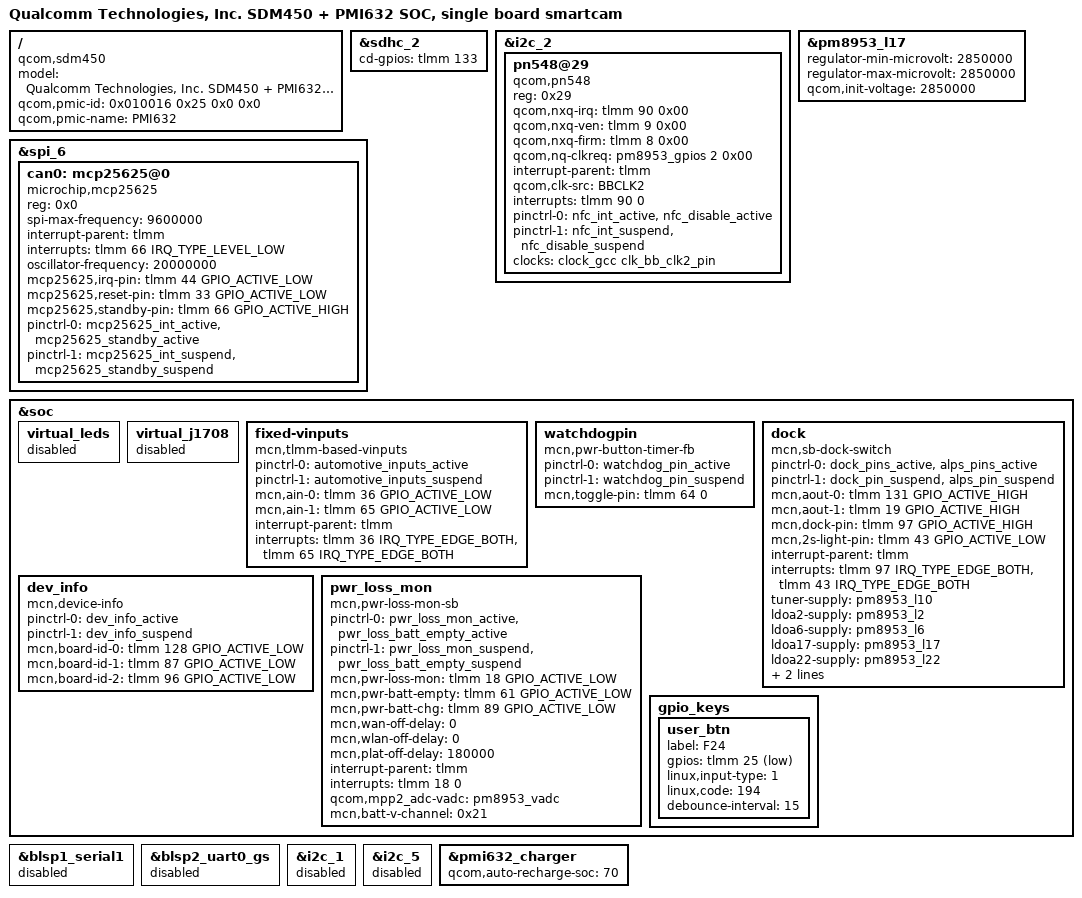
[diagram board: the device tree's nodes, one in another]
/*
 * Copyright (c) 2018, The Linux Foundation. All rights reserved.
 *
 * This program is free software; you can redistribute it and/or modify
 * it under the terms of the GNU General Public License version 2 and
 * only version 2 as published by the Free Software Foundation.
 *
 * This program is distributed in the hope that it will be useful,
 * but WITHOUT ANY WARRANTY; without even the implied warranty of
 * MERCHANTABILITY or FITNESS FOR A PARTICULAR PURPOSE.  See the
 * GNU General Public License for more details.
 */

/dts-v1/;

#include "sdm450-sb.dtsi"
#include "sdm450-pmi632-sb.dtsi"
#include "msm8953-pmi632-panel-camera.dtsi"

/ {
	model = "Qualcomm Technologies, Inc. SDM450 + PMI632 SOC, single board smartcam";
	compatible = "qcom,sdm450";
	qcom,pmic-id = <0x010016 0x25 0x0 0x0>;
	qcom,pmic-name = "PMI632";
};

&sdhc_2 {
	cd-gpios = <&tlmm 133 GPIO_ACTIVE_HIGH>;
};

&i2c_2 {
	status = "ok";
	pn548@29 {
		compatible = "qcom,pn548";
		reg = <0x29>;

		qcom,nxq-irq = <&tlmm 90 0x00>;
		qcom,nxq-ven = <&tlmm 9 0x00>;
		qcom,nxq-firm = <&tlmm 8 0x00>;
		qcom,nq-clkreq = <&pm8953_gpios 2 0x00>;
		interrupt-parent = <&tlmm>;
		qcom,clk-src = "BBCLK2";
		interrupts = <&tlmm 90 0>;
		interrupt-names = "nfc_irq";
		pinctrl-names = "nfc_active", "nfc_suspend";
		pinctrl-0 = <&nfc_int_active &nfc_disable_active>;
		pinctrl-1 = <&nfc_int_suspend &nfc_disable_suspend>;
		clocks = <&clock_gcc clk_bb_clk2_pin>;
		clock-names = "ref_clk";
		status = "ok";
	};
};

&spi_6 { /* BLSP2 QUP2 (CAN) */
	status = "ok";
	can0:mcp25625@0 {
		status = "ok";
		compatible = "microchip,mcp25625";
		reg = <0x0>;
		spi-max-frequency = <9600000>;
		interrupt-parent = <&tlmm>;
		interrupts = <&tlmm 66 IRQ_TYPE_LEVEL_LOW>;
		oscillator-frequency = <20000000>;
		/*clocks = <&can_osc_fixed>;*/
		/*avdd-supply = <&pm8916_lx>;
		dvdd-supply = <&pm8916_lx>;*/
		mcp25625,irq-pin = <&tlmm 44 GPIO_ACTIVE_LOW>;
		mcp25625,reset-pin = <&tlmm 33 GPIO_ACTIVE_LOW>;
		mcp25625,standby-pin = <&tlmm 66 GPIO_ACTIVE_HIGH>;
		pinctrl-names = "mcp25625_standby_active","mcp25625_standby_suspend";
		pinctrl-0 = <&mcp25625_int_active &mcp25625_standby_active>;
		pinctrl-1 = <&mcp25625_int_suspend &mcp25625_standby_suspend>;
	};
};

&pm8953_l17 {
	regulator-min-microvolt = <2850000>;
	regulator-max-microvolt = <2850000>;
	qcom,init-voltage = <2850000>;
};

&soc {
	virtual_leds {
		status = "disabled";
	};

	virtual_j1708 {
		status = "disabled";
	};

	fixed-vinputs {
		compatible = "mcn,tlmm-based-vinputs";
		pinctrl-names = "automotive_inputs_active", "automotive_inputs_suspend";
		pinctrl-0 = <&automotive_inputs_active>;
		pinctrl-1 = <&automotive_inputs_suspend>;
		mcn,ain-0 = <&tlmm 36 GPIO_ACTIVE_LOW>;
		mcn,ain-1 = <&tlmm 65 GPIO_ACTIVE_LOW>;
		interrupt-parent = <&tlmm>;
		interrupt-names = "ain-0", "ain-1";
		interrupts = <&tlmm 36 IRQ_TYPE_EDGE_BOTH>, <&tlmm 65 IRQ_TYPE_EDGE_BOTH>;
		status = "okay";
	};

	watchdogpin {
		compatible = "mcn,pwr-button-timer-fb";
		pinctrl-names = "watchdog_pin_active", "watchdog_pin_suspend";
		pinctrl-0 = <&watchdog_pin_active>;		
		pinctrl-1 = <&watchdog_pin_suspend>;
		mcn,toggle-pin = <&tlmm 64 0>;
		status = "okay";
	};

	dock {
		compatible = "mcn,sb-dock-switch";
		pinctrl-names = "dock_pins_active", "dock_pin_suspend";
		pinctrl-0 = <&dock_pins_active &alps_pins_active>;
		pinctrl-1 = <&dock_pin_suspend &alps_pin_suspend>;
		mcn,aout-0 = <&tlmm 131 GPIO_ACTIVE_HIGH>;
		mcn,aout-1 = <&tlmm 19 GPIO_ACTIVE_HIGH>;
		mcn,dock-pin = <&tlmm 97 GPIO_ACTIVE_HIGH>;
		mcn,2s-light-pin = <&tlmm 43 GPIO_ACTIVE_LOW>;
		interrupt-names = "ignition-changed", "light-changed";
		interrupt-parent = <&tlmm>;
		interrupts = <&tlmm 97 IRQ_TYPE_EDGE_BOTH>, <&tlmm 43 IRQ_TYPE_EDGE_BOTH>;
		tuner-supply = <&pm8953_l10>;
		ldoa2-supply = <&pm8953_l2>;
		ldoa6-supply = <&pm8953_l6>;
		ldoa17-supply = <&pm8953_l17>;
		ldoa22-supply = <&pm8953_l22>;
		ldoa23-supply = <&pm8953_l23>;
		qcom,ignition_v-vadc = <&pmi632_vadc>;
		status = "okay";
	};

	dev_info {
		compatible = "mcn,device-info";
		pinctrl-names = "dev_info_active", "dev_info_suspend";
		pinctrl-0 = <&dev_info_active>;
		pinctrl-1 = <&dev_info_suspend>;
		mcn,board-id-0 = <&tlmm 128 GPIO_ACTIVE_LOW>;
		mcn,board-id-1 = <&tlmm 87 GPIO_ACTIVE_LOW>;
		mcn,board-id-2 = <&tlmm 96 GPIO_ACTIVE_LOW>; 
		status = "okay";
	};

	pwr_loss_mon {
		compatible = "mcn,pwr-loss-mon-sb";
		pinctrl-names = "pwr_loss_mon_active", "pwr_loss_mon_suspend";
		pinctrl-0 = <&pwr_loss_mon_active &pwr_loss_batt_empty_active>;
		pinctrl-1 = <&pwr_loss_mon_suspend &pwr_loss_batt_empty_suspend>;
		mcn,pwr-loss-mon = <&tlmm 18 GPIO_ACTIVE_LOW>;
		mcn,pwr-batt-empty = <&tlmm 61 GPIO_ACTIVE_LOW>;
		mcn,pwr-batt-chg = <&tlmm 89 GPIO_ACTIVE_LOW>;
		mcn,wan-off-delay = <0>;
		mcn,wlan-off-delay = <0>;
		mcn,plat-off-delay = <180000>;
		/*mcn,plat-off-delay = <0xFFFFFFFF>;*/
		interrupt-names = "pwr-loss";
		interrupt-parent = <&tlmm>;
		interrupts = <&tlmm 18 0>;
		qcom,mpp2_adc-vadc = <&pm8953_vadc>;
		mcn,batt-v-channel = <0x21>;
		status = "okay";
	};

	gpio_keys {
		user_btn {
			label = "F24";
			gpios = <&tlmm 25 0x1>;
			linux,input-type = <1>;
			linux,code = <194>;
			debounce-interval = <15>;
		};
	};
};

&blsp1_serial1 {
	status = "disabled";
};

&blsp2_uart0_gs {
	status = "disabled";
};

&i2c_1  {
	status = "disabled";
};

&i2c_5  {
	status = "disabled";
};

/*
&pm8953_rtc {
	qcom,qpnp-rtc-write = <1>;
	qcom,qpnp-rtc-alarm-pwrup = <1>;
}
*/

&pmi632_charger {
	qcom,auto-recharge-soc = <70>;
};
